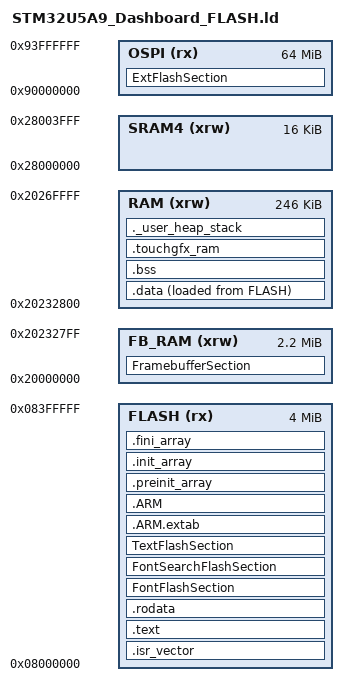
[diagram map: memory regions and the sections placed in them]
/*
******************************************************************************
**
** @file        : STM32U5A9_Dashboard_FLASH.ld
**
** @brief       : Project linker script for the PUTM EV dashboard
**                (STM32U5A9NJHxQ, 4096K FLASH, 2496K SRAM1/2/3/5,
**                 MX25LM51245G OctoSPI flash memory-mapped at 0x90000000).
**
** This file is NOT generated by STM32CubeMX. CubeMX creates
** STM32U5A9xx_FLASH.ld from its generic template whenever that file is
** missing and patches its heap/stack lines on every "Generate Code";
** this one has a different name so CubeMX never touches it.
** The root CMakeLists.txt points the linker here.
**
** Memory layout (same as the last working CubeIDE build, soft-v2.0):
**   FB_RAM 0x20000000..0x20232800  two 800x480 RGB888 framebuffers
**                                  (TouchGFXGeneratedHAL.cpp: 0x20000000 and
**                                   0x20119400, set "By Address" in CubeMX)
**   RAM    0x20232800..0x20270000  .data, .bss, FreeRTOS heap (in .bss),
**                                  NemaGFX pool, newlib heap and MSP stack
**   FLASH  0x08000000              code, rodata, TouchGFX fonts and texts
**   OSPI   0x90000000              TouchGFX images (ExtFlashSection)
**
** If you change the framebuffer addresses in TouchGFX/CubeMX, change FB_RAM
** here too. The ASSERTs at the end stop the link if they no longer fit.
******************************************************************************
*/

ENTRY(Reset_Handler)

/* Framebuffer geometry (must match TouchGFX: 800x480, 24 bpp, double buffer) */
__fb_width       = 800;
__fb_height      = 480;
__fb_bytes_pp    = 3;
__fb_size        = __fb_width * __fb_height * __fb_bytes_pp;   /* 0x119400 */
__fb_count       = 2;

/* Highest address of the user mode stack */
_estack = ORIGIN(RAM) + LENGTH(RAM);    /* 0x20270000, end of SRAM5 */

_Min_Heap_Size  = 0x8000;   /* required amount of newlib heap (malloc) */
_Min_Stack_Size = 0x8000;   /* required amount of MSP stack */

MEMORY
{
  FB_RAM (xrw) : ORIGIN = 0x20000000, LENGTH = 2250K  /* 0x232800 = 2 x 0x119400 */
  RAM    (xrw) : ORIGIN = 0x20232800, LENGTH = 246K   /* up to 0x20270000 */
  SRAM4  (xrw) : ORIGIN = 0x28000000, LENGTH = 16K
  FLASH  (rx)  : ORIGIN = 0x08000000, LENGTH = 4096K
  OSPI   (rx)  : ORIGIN = 0x90000000, LENGTH = 64M    /* MX25LM51245G, memory-mapped */
}

/* Exported for application code that wants the addresses instead of literals */
PROVIDE(__framebuffer0_start = ORIGIN(FB_RAM));
PROVIDE(__framebuffer1_start = ORIGIN(FB_RAM) + __fb_size);

SECTIONS
{
  /* Vector table */
  .isr_vector :
  {
    . = ALIGN(4);
    KEEP(*(.isr_vector))
    . = ALIGN(4);
  } >FLASH

  /* Code */
  .text :
  {
    . = ALIGN(4);
    *(.text)
    *(.text*)
    *(.glue_7)
    *(.glue_7t)
    *(.eh_frame)

    KEEP (*(.init))
    KEEP (*(.fini))

    . = ALIGN(4);
    _etext = .;
  } >FLASH

  /* Constants */
  .rodata :
  {
    . = ALIGN(4);
    *(.rodata)
    *(.rodata*)
    . = ALIGN(4);
  } >FLASH

  /* TouchGFX fonts and texts (internal flash, read directly by the CPU) */
  FontFlashSection :
  {
    . = ALIGN(4);
    *(FontFlashSection FontFlashSection.*)
    . = ALIGN(4);
  } >FLASH

  FontSearchFlashSection :
  {
    . = ALIGN(4);
    *(FontSearchFlashSection FontSearchFlashSection.*)
    . = ALIGN(4);
  } >FLASH

  TextFlashSection :
  {
    . = ALIGN(4);
    *(TextFlashSection TextFlashSection.*)
    . = ALIGN(4);
  } >FLASH

  .ARM.extab (READONLY) :
  {
    . = ALIGN(4);
    *(.ARM.extab* .gnu.linkonce.armextab.*)
    . = ALIGN(4);
  } >FLASH

  .ARM (READONLY) :
  {
    . = ALIGN(4);
    __exidx_start = .;
    *(.ARM.exidx*)
    __exidx_end = .;
    . = ALIGN(4);
  } >FLASH

  .preinit_array (READONLY) :
  {
    . = ALIGN(4);
    PROVIDE_HIDDEN (__preinit_array_start = .);
    KEEP (*(.preinit_array*))
    PROVIDE_HIDDEN (__preinit_array_end = .);
    . = ALIGN(4);
  } >FLASH

  .init_array (READONLY) :
  {
    . = ALIGN(4);
    PROVIDE_HIDDEN (__init_array_start = .);
    KEEP (*(SORT(.init_array.*)))
    KEEP (*(.init_array*))
    PROVIDE_HIDDEN (__init_array_end = .);
    . = ALIGN(4);
  } >FLASH

  .fini_array (READONLY) :
  {
    . = ALIGN(4);
    PROVIDE_HIDDEN (__fini_array_start = .);
    KEEP (*(SORT(.fini_array.*)))
    KEEP (*(.fini_array*))
    PROVIDE_HIDDEN (__fini_array_end = .);
    . = ALIGN(4);
  } >FLASH

  /* Used by the startup to initialize data */
  _sidata = LOADADDR(.data);

  /* Initialized data: lives in RAM, copied from FLASH by Reset_Handler */
  .data :
  {
    . = ALIGN(4);
    _sdata = .;
    *(.data)
    *(.data*)
    *(.RamFunc)
    *(.RamFunc*)
    . = ALIGN(4);
    _edata = .;
  } >RAM AT> FLASH

  /* Zero-initialized data (FreeRTOS ucHeap lives here) */
  .bss (NOLOAD) :
  {
    . = ALIGN(4);
    _sbss = .;
    __bss_start__ = _sbss;
    *(.bss)
    *(.bss*)
    *(COMMON)
    . = ALIGN(4);
    _ebss = .;
    __bss_end__ = _ebss;
  } >RAM

  /* Uninitialized TouchGFX / NemaGFX buffers. Without these rules GCC places
     them as orphan sections between .data and .bss with a FLASH load
     address. They need no init, so keep them NOLOAD in RAM. */
  .touchgfx_ram (NOLOAD) :
  {
    . = ALIGN(32);
    *(Nemagfx_Memory_Pool_Buffer Nemagfx_Memory_Pool_Buffer.*)
    . = ALIGN(32);
    *(TouchGFX_ScratchbufferA TouchGFX_ScratchbufferA.*)
    *(TouchGFX_ScratchbufferB TouchGFX_ScratchbufferB.*)
    . = ALIGN(32);
    *(TouchGFX_CompressedFontCache TouchGFX_CompressedFontCache.*)
    *(TouchGFX_CompressedUnmappedFontCache TouchGFX_CompressedUnmappedFontCache.*)
    . = ALIGN(4);
  } >RAM

  /* newlib heap + MSP stack reservation (link fails if RAM is too small) */
  ._user_heap_stack (NOLOAD) :
  {
    . = ALIGN(8);
    PROVIDE ( end = . );
    PROVIDE ( _end = . );
    . = . + _Min_Heap_Size;
    . = . + _Min_Stack_Size;
    . = ALIGN(8);
  } >RAM

  /* Framebuffers. TouchGFX uses fixed addresses ("By Address"), so this is
     normally empty; it only reserves FB_RAM so nothing else lands there. */
  FramebufferSection (NOLOAD) :
  {
    *(TouchGFX_Framebuffer TouchGFX_Framebuffer.*)
    . = ALIGN(4);
  } >FB_RAM

  /* TouchGFX images in the external OctoSPI flash. Programmed with the
     MX25LM51245G external loader; read only after the flash is put in
     memory-mapped mode (before MX_TouchGFX_Init). */
  ExtFlashSection :
  {
    . = ALIGN(4);
    *(ExtFlashSection ExtFlashSection.*)
    . = ALIGN(4);
  } >OSPI

  /* Remove information from the compiler libraries */
  /DISCARD/ :
  {
    libc.a ( * )
    libm.a ( * )
    libgcc.a ( * )
  }

  .ARM.attributes 0 : { *(.ARM.attributes) }
}

/* Sanity checks */
ASSERT(LENGTH(FB_RAM) >= __fb_count * __fb_size,
       "FB_RAM is too small for two 800x480x24bpp framebuffers")
ASSERT(ORIGIN(RAM) >= ORIGIN(FB_RAM) + __fb_count * __fb_size,
       "RAM overlaps the TouchGFX framebuffers")
ASSERT(ORIGIN(RAM) + LENGTH(RAM) <= 0x20270000,
       "RAM goes past the end of SRAM5 (0x20270000)")
ASSERT(SIZEOF(FramebufferSection) == 0 || SIZEOF(FramebufferSection) <= LENGTH(FB_RAM),
       "TouchGFX_Framebuffer section does not fit in FB_RAM")
